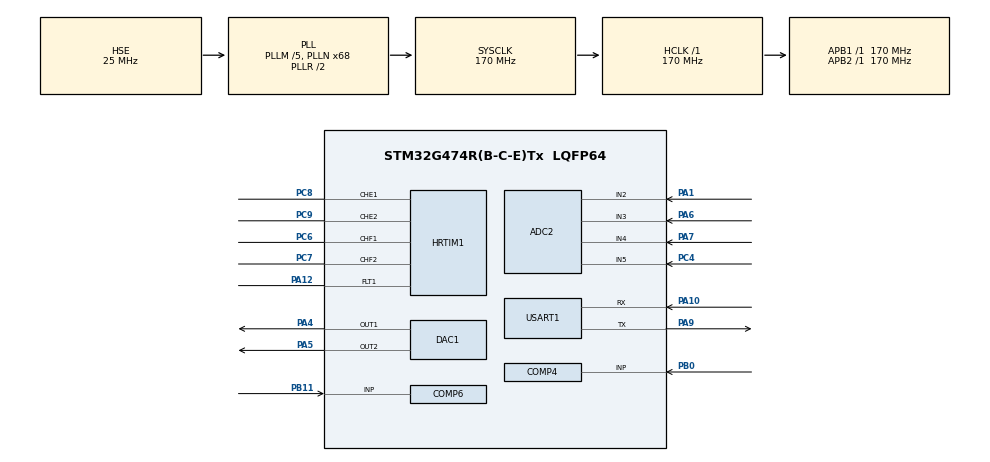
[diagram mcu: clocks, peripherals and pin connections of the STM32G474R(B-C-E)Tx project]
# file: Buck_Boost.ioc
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ADC2.Channel-0\#ChannelRegularConversion=ADC_CHANNEL_2
ADC2.EOCSelection=ADC_EOC_SEQ_CONV
ADC2.EnableInjectedConversion=ENABLE
ADC2.ExternalTrigInjecConv=ADC_EXTERNALTRIGINJEC_HRTIM_TRG4
ADC2.InjNumberOfConversion=4
ADC2.InjectedChannel-1\#ChannelInjectedConversion=ADC_CHANNEL_2
ADC2.InjectedChannel-2\#ChannelInjectedConversion=ADC_CHANNEL_3
ADC2.InjectedChannel-3\#ChannelInjectedConversion=ADC_CHANNEL_4
ADC2.InjectedChannel-4\#ChannelInjectedConversion=ADC_CHANNEL_5
ADC2.InjectedOffsetNumber-1\#ChannelInjectedConversion=ADC_OFFSET_NONE
ADC2.InjectedOffsetNumber-2\#ChannelInjectedConversion=ADC_OFFSET_NONE
ADC2.InjectedOffsetNumber-3\#ChannelInjectedConversion=ADC_OFFSET_NONE
ADC2.InjectedOffsetNumber-4\#ChannelInjectedConversion=ADC_OFFSET_NONE
ADC2.InjectedRank-1\#ChannelInjectedConversion=1
ADC2.InjectedRank-2\#ChannelInjectedConversion=2
ADC2.InjectedRank-3\#ChannelInjectedConversion=3
ADC2.InjectedRank-4\#ChannelInjectedConversion=4
ADC2.InjectedSamplingTime-1\#ChannelInjectedConversion=ADC_SAMPLETIME_2CYCLES_5
ADC2.InjectedSamplingTime-2\#ChannelInjectedConversion=ADC_SAMPLETIME_2CYCLES_5
ADC2.InjectedSamplingTime-3\#ChannelInjectedConversion=ADC_SAMPLETIME_2CYCLES_5
ADC2.InjectedSamplingTime-4\#ChannelInjectedConversion=ADC_SAMPLETIME_2CYCLES_5
ADC2.NbrOfConversionFlag=1
ADC2.OffsetNumber-0\#ChannelRegularConversion=ADC_OFFSET_NONE
ADC2.Overrun=ADC_OVR_DATA_OVERWRITTEN
ADC2.Rank-0\#ChannelRegularConversion=1
ADC2.Rank1_Channel=ADC_CHANNEL_2
ADC2.Rank2_Channel=ADC_CHANNEL_3
ADC2.Rank3_Channel=ADC_CHANNEL_4
ADC2.Rank4_Channel=ADC_CHANNEL_5
ADC2.SamplingTime-0\#ChannelRegularConversion=ADC_SAMPLETIME_2CYCLES_5
COMP4.Hysteresis=COMP_HYSTERESIS_LOW
COMP6.Hysteresis=COMP_HYSTERESIS_LOW
DAC1.DAC_Channel-DAC_OUT2=DAC_CHANNEL_2
DAC3.DAC_Channel-DAC_OUT2_Int=DAC_CHANNEL_2
DAC4.DAC_Channel-DAC_OUT2_Int=DAC_CHANNEL_2
HRTIM1.ADCTrigger4_Source1=HRTIM_ADCTRIGGEREVENT24_MASTER_CMP4
HRTIM1.ADCTrigger_Id1=__NULL
HRTIM1.ADCTrigger_Id4=HRTIM_ADCTRIGGER_4
HRTIM1.CompareUnit1-Output_TE1TE2=HRTIM_COMPAREUNIT_1
HRTIM1.CompareUnit1-Output_TF1TF2=HRTIM_COMPAREUNIT_1
HRTIM1.CompareUnit2-MasterTimer=__NULL
HRTIM1.CompareUnit2-Output_TE1TE2=__NULL
HRTIM1.CompareUnit3-Output_TE1TE2=HRTIM_COMPAREUNIT_3
HRTIM1.CompareUnit3-Output_TF1TF2=HRTIM_COMPAREUNIT_3
HRTIM1.CompareUnit4-MasterTimer=HRTIM_COMPAREUNIT_4
HRTIM1.CompareValue1-Output_TE1TE2=6800
HRTIM1.CompareValue1-Output_TF1TF2=6800
HRTIM1.CompareValue3-Output_TE1TE2=27200
HRTIM1.CompareValue3-Output_TF1TF2=27200
HRTIM1.CompareValue4-MasterTimer=6800
HRTIM1.DeadTimeInsertion-Output_TE1TE2=HRTIM_TIMDEADTIMEINSERTION_ENABLED
HRTIM1.DeadTimeInsertion-Output_TF1TF2=HRTIM_TIMDEADTIMEINSERTION_ENABLED
HRTIM1.FallingValue-Output_TE1TE2=4
HRTIM1.FallingValue-Output_TF1TF2=4
HRTIM1.FaultEnable_Source1-Output_TE1TE2=HRTIM_TIMFAULTENABLE_FAULT1
HRTIM1.FaultEnable_Source1-Output_TF1TF2=HRTIM_TIMFAULTENABLE_FAULT1
HRTIM1.FaultEnable_Source2-Output_TE1TE2=HRTIM_TIMFAULTENABLE_FAULT2
HRTIM1.FaultEnable_Source2-Output_TF1TF2=HRTIM_TIMFAULTENABLE_FAULT2
HRTIM1.FaultEnable_Source3-Output_TE1TE2=HRTIM_TIMFAULTENABLE_FAULT3
HRTIM1.FaultEnable_Source3-Output_TF1TF2=HRTIM_TIMFAULTENABLE_FAULT3
HRTIM1.FaultLevel1-Output_TE1TE2=HRTIM_OUTPUTFAULTLEVEL_INACTIVE
HRTIM1.FaultLevel1-Output_TF1TF2=HRTIM_OUTPUTFAULTLEVEL_INACTIVE
HRTIM1.FaultLevel2-Output_TE1TE2=HRTIM_OUTPUTFAULTLEVEL_INACTIVE
HRTIM1.FaultLevel2-Output_TF1TF2=HRTIM_OUTPUTFAULTLEVEL_INACTIVE
HRTIM1.Fault_Line2=HRTIM_FAULT_2
HRTIM1.Fault_Line3=HRTIM_FAULT_3
HRTIM1.Filter_FaultLine1=HRTIM_FAULTFILTER_1
HRTIM1.HRTIMInterruptResquests1=HRTIM_IT_FLT1
HRTIM1.HRTIMInterruptResquests2=HRTIM_IT_FLT2
HRTIM1.HRTIMInterruptResquests3=HRTIM_IT_FLT3
HRTIM1.NumberADCTriggerSource4=1
HRTIM1.NumberFaultEnable-Output_TE1TE2=3
HRTIM1.NumberFaultEnable-Output_TF1TF2=3
HRTIM1.NumberResetSource1-Output_TE1TE2=1
HRTIM1.NumberResetSource1-Output_TF1TF2=1
HRTIM1.NumberResetTrigger-Output_TE1TE2=1
HRTIM1.NumberResetTrigger-Output_TF1TF2=1
HRTIM1.NumberSetSource1-Output_TE1TE2=1
HRTIM1.NumberSetSource1-Output_TF1TF2=1
HRTIM1.Periode_MASTER=27200
HRTIM1.Periode_TE=27200
HRTIM1.Periode_TF=27200
HRTIM1.Polarity_FaultLine1=HRTIM_FAULTPOLARITY_LOW
HRTIM1.PreloadEnable-MasterTimer=HRTIM_PRELOAD_ENABLED
HRTIM1.PreloadEnable-Output_TE1TE2=HRTIM_PRELOAD_ENABLED
HRTIM1.PreloadEnable-Output_TF1TF2=HRTIM_PRELOAD_ENABLED
HRTIM1.PrescalerDead-Output_TE1TE2=HRTIM_TIMDEADTIME_PRESCALERRATIO_DIV1
HRTIM1.PrescalerDead-Output_TF1TF2=HRTIM_TIMDEADTIME_PRESCALERRATIO_DIV1
HRTIM1.RepetitionUpdate-MasterTimer=HRTIM_UPDATEONREPETITION_ENABLED
HRTIM1.RepetitionUpdate-Output_TE1TE2=HRTIM_UPDATEONREPETITION_ENABLED
HRTIM1.RepetitionUpdate-Output_TF1TF2=HRTIM_UPDATEONREPETITION_ENABLED
HRTIM1.ResetOutput1_Source1-Output_TE1TE2=HRTIM_OUTPUTRESET_TIMCMP3
HRTIM1.ResetOutput1_Source1-Output_TF1TF2=HRTIM_OUTPUTRESET_TIMCMP3
HRTIM1.RisingValue-Output_TE1TE2=4
HRTIM1.RisingValue-Output_TF1TF2=4
HRTIM1.SetOutput1_Source1-Output_TE1TE2=HRTIM_OUTPUTSET_TIMCMP1
HRTIM1.SetOutput1_Source1-Output_TF1TF2=HRTIM_OUTPUTSET_TIMCMP1
Mcu.Family=STM32G4
Mcu.Name=STM32G474R(B-C-E)Tx
Mcu.Package=LQFP64
NVIC.ADC1_2_IRQn=true\:0\:0\:false\:false\:true\:true\:true\:true
NVIC.HRTIM1_FLT_IRQn=true\:0\:0\:false\:false\:true\:true\:true\:true
NVIC.HRTIM1_TIME_IRQn=true\:0\:0\:false\:false\:true\:true\:true\:true
NVIC.HRTIM1_TIMF_IRQn=true\:0\:0\:false\:false\:true\:true\:true\:true
NVIC.PriorityGroup=NVIC_PRIORITYGROUP_4
PA1.Mode=IN2-Single-Ended
PA1.Signal=ADC2_IN2
PA10.Mode=Asynchronous
PA10.Signal=USART1_RX
PA12.Mode=Fault_Enable1
PA12.Signal=HRTIM1_FLT1
PA13.Mode=Serial_Wire
PA13.Signal=SYS_JTMS-SWDIO
PA14.Mode=Serial_Wire
PA14.Signal=SYS_JTCK-SWCLK
PA4.Signal=COMP_DAC11_group
PA5.Signal=COMP_DAC12_group
PA6.Mode=IN3-Single-Ended
PA6.Signal=ADC2_IN3
PA7.Mode=IN4-Single-Ended
PA7.Signal=ADC2_IN4
PA9.Mode=Asynchronous
PA9.Signal=USART1_TX
PB0.Mode=INP
PB0.Signal=COMP4_INP
PB11.Mode=INP
PB11.Signal=COMP6_INP
PC4.Mode=IN5-Single-Ended
PC4.Signal=ADC2_IN5
PC6.Mode=Output_TF1TF2
PC6.Signal=HRTIM1_CHF1
PC7.Mode=Output_TF1TF2
PC7.Signal=HRTIM1_CHF2
PC8.Mode=Output_TE1TE2
PC8.Signal=HRTIM1_CHE1
PC9.Mode=Output_TE1TE2
PC9.Signal=HRTIM1_CHE2
PF0-OSC_IN.Mode=HSE-External-Oscillator
PF0-OSC_IN.Signal=RCC_OSC_IN
PF1-OSC_OUT.Mode=HSE-External-Oscillator
PF1-OSC_OUT.Signal=RCC_OSC_OUT
ProjectManager.HeapSize=0x200
ProjectManager.StackSize=0x400
ProjectManager.TargetToolchain=STM32CubeIDE
RCC.ADC12Freq_Value=170000000
RCC.ADC345Freq_Value=170000000
RCC.AHBFreq_Value=170000000
RCC.APB1Freq_Value=170000000
RCC.APB1TimFreq_Value=170000000
RCC.APB2Freq_Value=170000000
RCC.APB2TimFreq_Value=170000000
RCC.CortexFreq_Value=170000000
RCC.EXTERNAL_CLOCK_VALUE=12288000
RCC.HCLKFreq_Value=170000000
RCC.HSE_VALUE=25000000
RCC.HSI48_VALUE=48000000
RCC.HSI_VALUE=16000000
RCC.LSE_VALUE=32768
RCC.PLLM=RCC_PLLM_DIV5
RCC.PLLN=68
RCC.PLLSourceVirtual=RCC_PLLSOURCE_HSE
RCC.SYSCLKFreq_VALUE=170000000
RCC.SYSCLKSource=RCC_SYSCLKSOURCE_PLLCLK
RCC.USBFreq_Value=170000000
RCC.VCOOutputFreq_Value=340000000
SH.COMP_DAC11_group.0=DAC1_OUT1,DAC_OUT1
SH.COMP_DAC12_group.0=DAC1_OUT2,DAC_OUT2
USART1.VirtualMode-Asynchronous=VM_ASYNC
VP_COMP4_VS_DAC3OUT2.Mode=INM_DAC3OUT2
VP_COMP6_VS_DAC4OUT2.Mode=INM_DAC4OUT2
VP_DAC3_VS_DACI2.Mode=DAC_OUT2_Int
VP_DAC4_VS_DACI2.Mode=DAC_OUT2_Int
VP_HRTIM1_VS_hrtimMasterTimerNoOutput.Mode=MasterTimer
VP_SYS_VS_DBSignals.Mode=DisableDeadBatterySignals
board=custom

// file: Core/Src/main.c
/* USER CODE BEGIN Header */
/**
  ******************************************************************************
  * @file           : main.c
  * @brief          : Main program body
  ******************************************************************************
  * @attention
  *
  * Copyright (c) 2026 STMicroelectronics.
  * All rights reserved.
  *
  * This software is licensed under terms that can be found in the LICENSE file
  * in the root directory of this software component.
  * If no LICENSE file comes with this software, it is provided AS-IS.
  *
  ******************************************************************************
  */
/* USER CODE END Header */
#include "main.h"
#include "adc.h"
#include "comp.h"
#include "dac.h"
#include "hrtim.h"
#include "usart.h"
#include "gpio.h"

/* USER CODE BEGIN Includes */
#include "Global_Inc.h"
/* USER CODE END Includes */

void SystemClock_Config(void);

int main(void)
{

  /* MCU Configuration--------------------------------------------------------*/

  /* Reset of all peripherals, Initializes the Flash interface and the Systick. */
  HAL_Init();

  /* Configure the system clock */
  SystemClock_Config();

  /* Initialize all configured peripherals */
  MX_GPIO_Init();
  MX_USART1_UART_Init();
  MX_HRTIM1_Init();
  MX_COMP4_Init();
  MX_COMP6_Init();
  MX_DAC3_Init();
  MX_DAC4_Init();
  MX_ADC2_Init();
  MX_DAC1_Init();
  /* USER CODE BEGIN 2 */
  APP_SysInit();
  APP_DualLoopInit(&currLoop, &volLoop);
  /* USER CODE END 2 */

  /* Infinite loop */
  /* USER CODE BEGIN WHILE */

  /* 以下为ADC调试函数 */
//  if (HAL_ADC_Calibration_Start() != HAL_OK){
//	  Error_Handler();
//  }
//
//  if (HAL_ADCEx_InjectedStart_IT(&hadc2) != HAL_OK){
//      Error_Handler();
//  }
//
//  /* 当前只启动产生 ADC 触发的主计数器 */
//  if (HAL_HRTIM_WaveformCountStart(&hhrtim1, HRTIM_TIMERID_MASTER) != HAL_OK){
//      Error_Handler();
//  }

  while (1)
  {
    /* USER CODE END WHILE */

  }
}

void SystemClock_Config(void)
{
  RCC_OscInitTypeDef RCC_OscInitStruct = {0};
  RCC_ClkInitTypeDef RCC_ClkInitStruct = {0};

  /** Configure the main internal regulator output voltage
  */
  HAL_PWREx_ControlVoltageScaling(PWR_REGULATOR_VOLTAGE_SCALE1_BOOST);

  /** Initializes the RCC Oscillators according to the specified parameters
  * in the RCC_OscInitTypeDef structure.
  */
  RCC_OscInitStruct.OscillatorType = RCC_OSCILLATORTYPE_HSE;
  RCC_OscInitStruct.HSEState = RCC_HSE_ON;
  RCC_OscInitStruct.PLL.PLLState = RCC_PLL_ON;
  RCC_OscInitStruct.PLL.PLLSource = RCC_PLLSOURCE_HSE;
  RCC_OscInitStruct.PLL.PLLM = RCC_PLLM_DIV5;
  RCC_OscInitStruct.PLL.PLLN = 68;
  RCC_OscInitStruct.PLL.PLLP = RCC_PLLP_DIV2;
  RCC_OscInitStruct.PLL.PLLQ = RCC_PLLQ_DIV2;
  RCC_OscInitStruct.PLL.PLLR = RCC_PLLR_DIV2;
  if (HAL_RCC_OscConfig(&RCC_OscInitStruct) != HAL_OK)
  {
    Error_Handler();
  }

  /** Initializes the CPU, AHB and APB buses clocks
  */
  RCC_ClkInitStruct.ClockType = RCC_CLOCKTYPE_HCLK|RCC_CLOCKTYPE_SYSCLK
                              |RCC_CLOCKTYPE_PCLK1|RCC_CLOCKTYPE_PCLK2;
  RCC_ClkInitStruct.SYSCLKSource = RCC_SYSCLKSOURCE_PLLCLK;
  RCC_ClkInitStruct.AHBCLKDivider = RCC_SYSCLK_DIV1;
  RCC_ClkInitStruct.APB1CLKDivider = RCC_HCLK_DIV1;
  RCC_ClkInitStruct.APB2CLKDivider = RCC_HCLK_DIV1;

  if (HAL_RCC_ClockConfig(&RCC_ClkInitStruct, FLASH_LATENCY_4) != HAL_OK)
  {
    Error_Handler();
  }
}

void Error_Handler(void)
{
  __disable_irq();
  while (1)
  {
  }
}
